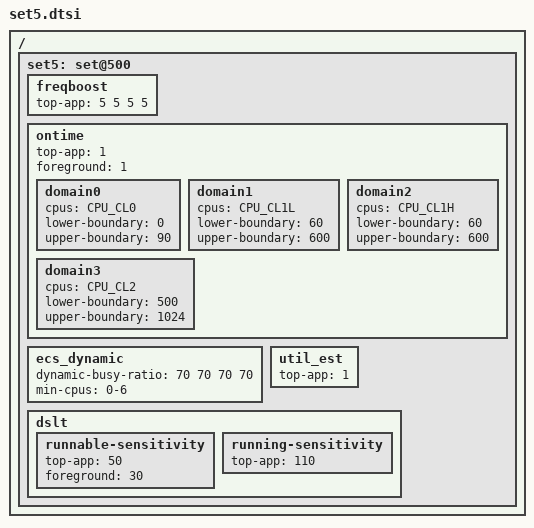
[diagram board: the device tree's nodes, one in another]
/ {
	/* camera mode - default */
	set5: set@500 {
		/* Boosting margin applied to frequency selection */
		freqboost {			/* LIT MED-L MED-H BIG */
			top-app			= <  5   5   5   5 >;
		};

		/* Ontime Migration */
		ontime {
			top-app		= <1>;
			foreground	= <1>;

			domain0 {
				cpus = CPU_CL0;
				lower-boundary = <0>;
				upper-boundary = <90>;
			};
			domain1 {
				cpus = CPU_CL1L;
				lower-boundary = <60>;
				upper-boundary = <600>;
			};
			domain2 {
				cpus = CPU_CL1H;
				lower-boundary = <60>;
				upper-boundary = <600>;
			};
			domain3 {
				cpus = CPU_CL2;
				lower-boundary = <500>;
				upper-boundary = <1024>;
			};
		};

		ecs_dynamic {
			dynamic-busy-ratio		= <70 70 70 70>;
			min-cpus = "0-6";
		};

		util_est {
			top-app	= <1>;
		};

		dslt {
			runnable-sensitivity {
				top-app    = <50>;
				foreground = <30>;
			};
			running-sensitivity {
				top-app    = <110>;
			};
		};
	};
};
